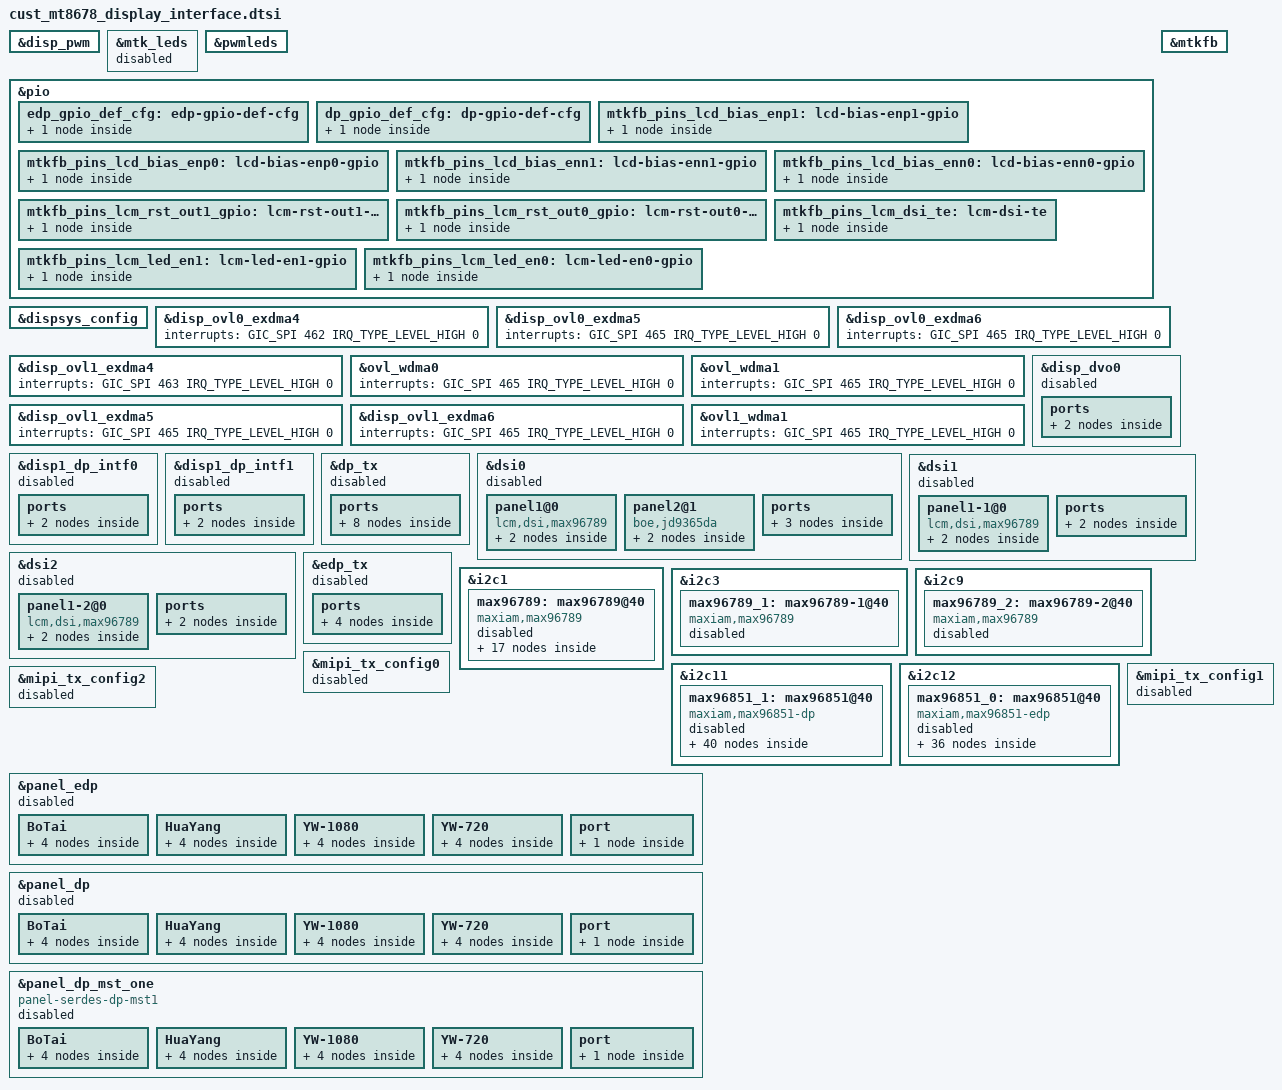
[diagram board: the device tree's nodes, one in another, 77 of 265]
// SPDX-License-Identifier: (GPL-2.0 OR MIT)
/*
 * Copyright (C) 2022 MediaTek Inc.
 */

&disp_pwm {
	status = "okay";
};
&mtk_leds {
	status = "disabled";
};
&pwmleds {
	status = "okay";
};

&pio {
	edp_gpio_def_cfg: edp-gpio-def-cfg{
		pins1 {
			pinmux = <PINMUX_GPIO8__FUNC_EDP_TX_HPD>;
		};
	};

	dp_gpio_def_cfg: dp-gpio-def-cfg {
		pins1 {
			pinmux = <PINMUX_GPIO118__FUNC_DP_TX_HPD>;
		};
	};

	mtkfb_pins_lcd_bias_enp1: lcd-bias-enp1-gpio {
		pins-cmd-dat {
			pinmux = <PINMUX_GPIO103__FUNC_GPIO103>;
			slew-rate = <1>;
			output-high;
		};
	};

	mtkfb_pins_lcd_bias_enp0: lcd-bias-enp0-gpio {
		pins-cmd-dat {
			pinmux = <PINMUX_GPIO103__FUNC_GPIO103>;
			slew-rate = <1>;
			output-low;
		};
	};

	mtkfb_pins_lcd_bias_enn1: lcd-bias-enn1-gpio {
		pins-cmd-dat {
			pinmux = <PINMUX_GPIO103__FUNC_GPIO103>;
			slew-rate = <1>;
			output-high;
		};
	};

	mtkfb_pins_lcd_bias_enn0: lcd-bias-enn0-gpio {
		pins-cmd-dat {
			pinmux = <PINMUX_GPIO103__FUNC_GPIO103>;
			slew-rate = <1>;
			output-low;
		};
	};

	mtkfb_pins_lcm_rst_out1_gpio: lcm-rst-out1-gpio {
		pins-cmd-dat {
			pinmux = <PINMUX_GPIO90__FUNC_GPIO90>;
			slew-rate = <1>;
			output-high;
		};
	};

	mtkfb_pins_lcm_rst_out0_gpio: lcm-rst-out0-gpio {
		pins-cmd-dat {
			pinmux = <PINMUX_GPIO90__FUNC_GPIO90>;
			slew-rate = <1>;
			output-low;
		};
	};
	mtkfb_pins_lcm_dsi_te: lcm-dsi-te {
		pins-cmd-dat {
			pinmux = <PINMUX_GPIO89__FUNC_DSI_TE>;
		};
	};

	mtkfb_pins_lcm_led_en1: lcm-led-en1-gpio {
		pins-cmd-dat {
			pinmux = <PINMUX_GPIO79__FUNC_GPIO79>;
			slew-rate = <1>;
			output-high;
		};
	};

	mtkfb_pins_lcm_led_en0: lcm-led-en0-gpio {
		pins-cmd-dat {
			pinmux = <PINMUX_GPIO79__FUNC_GPIO79>;
			slew-rate = <1>;
			output-low;
		};
	};
};

&mtkfb {
	pinctrl-names = "lcd_bias_enp1_gpio", "lcd_bias_enp0_gpio",
		"lcd_bias_enn1_gpio", "lcd_bias_enn0_gpio",
		"lcm_rst_out1_gpio", "lcm_rst_out0_gpio",
		"mode_te_te", "lcm_led_en1_gpio", "lcm_led_en0_gpio";
	pinctrl-0 = <&mtkfb_pins_lcd_bias_enp1>;
	pinctrl-1 = <&mtkfb_pins_lcd_bias_enp0>;
	pinctrl-2 = <&mtkfb_pins_lcd_bias_enn1>;
	pinctrl-3 = <&mtkfb_pins_lcd_bias_enn0>;
	pinctrl-4 = <&mtkfb_pins_lcm_rst_out1_gpio>;
	pinctrl-5 = <&mtkfb_pins_lcm_rst_out0_gpio>;
	pinctrl-6 = <&mtkfb_pins_lcm_dsi_te>;
	pinctrl-7 = <&mtkfb_pins_lcm_led_en1>;
	pinctrl-8 = <&mtkfb_pins_lcm_led_en0>;

	status = "okay";
};

&dispsys_config {
	pinctrl-names = "mode_te_te";
	pinctrl-0 = <&mtkfb_pins_lcm_dsi_te>;
	pd-others = <&disp1_mutex0>, <&disp_ovl0_exdma3>, <&disp_ovl1_exdma3>,
			<&disp_dpc>, <&mipi_tx_config0>, <&mipi_tx_config1>, <&mipi_tx_config2>;
	pd-names = "side_dispsys", "ovlsys", "side_ovlsys",
			"mminfra_in_dpc", "dsi_phy0", "dsi_phy1", "dsi_phy2";
	status = "okay";
};

&disp_ovl0_exdma4{
	interrupts = <GIC_SPI 462 IRQ_TYPE_LEVEL_HIGH 0>;
};

&disp_ovl0_exdma5 {
	interrupts = <GIC_SPI 465 IRQ_TYPE_LEVEL_HIGH 0>;
};

&disp_ovl0_exdma6 {
	interrupts = <GIC_SPI 465 IRQ_TYPE_LEVEL_HIGH 0>;
};

&disp_ovl1_exdma4{
	interrupts = <GIC_SPI 463 IRQ_TYPE_LEVEL_HIGH 0>;
};

&ovl_wdma0 {
	interrupts = <GIC_SPI 465 IRQ_TYPE_LEVEL_HIGH 0>;
};

&ovl_wdma1 {
	interrupts = <GIC_SPI 465 IRQ_TYPE_LEVEL_HIGH 0>;
};

&disp_ovl1_exdma5 {
	interrupts = <GIC_SPI 465 IRQ_TYPE_LEVEL_HIGH 0>;
};

&disp_ovl1_exdma6 {
	interrupts = <GIC_SPI 465 IRQ_TYPE_LEVEL_HIGH 0>;
};

&ovl1_wdma1 {
	interrupts = <GIC_SPI 465 IRQ_TYPE_LEVEL_HIGH 0>;
};

&disp_dvo0 {
	status = "disabled";
	ports {
		port {
			disp_dvo0_out: endpoint {
				remote-endpoint = <&edptx_in>;
			};
		};
	};
};

&disp1_dp_intf0 {
	status = "disabled";

	ports {
		port@0 {
			reg = <0>;
			disp1_dp_intf0_out: endpoint {
				remote-endpoint = <&dptx_in0>;
			};
		};
	};
};

&disp1_dp_intf1 {
	status = "disabled";

	ports {
		port@0 {
			reg = <0>;
			disp1_dp_intf1_out: endpoint {
				remote-endpoint = <&dptx_in1>;
			};
		};
	};
};

&dp_tx {
	pinctrl-names = "default";
	pinctrl-0 = <&dp_gpio_def_cfg>;
	status = "disabled";
	direct-dp;

	ports {
		port@0 {
			reg = <0>;
			dptx_in0: endpoint {
				remote-endpoint = <&disp1_dp_intf0_out>;
			};
		};

		port@1 {
			reg = <1>;
			dptx_in1: endpoint {
				remote-endpoint = <&disp1_dp_intf1_out>;
			};
		};

		port@2 {
			reg = <2>;
			dptx_out0: endpoint {
				remote-endpoint = <&serdes_dp_in0>;
			};
		};
		port@3 {
			reg = <3>;
			dptx_out1: endpoint {
				remote-endpoint = <&serdes_dp_mst_in1>;
			};
		};
	};
};

&dsi0 {
	status = "disabled";
	#address-cells = <1>;
	#size-cells = <0>;
	panel1@0 {
		compatible = "lcm,dsi,max96789";
		reg = <0>;

		ser = <&max96789>;
		port {
			panel_in1: endpoint {
				remote-endpoint = <&dsi_out>;
			};
		};
	};
	panel2@1 {
		compatible = "boe,jd9365da";
		reg = <1>;
		power-gpios = <&pio 79 0>;
		reset-gpios = <&pio 90 0>;
		pinctrl-names = "default";
		port {
			panel_in2: endpoint {
				remote-endpoint = <&dsi_out2>;
			};
		};
	};
	ports {
		port {
			dsi_out: endpoint@0 {
				remote-endpoint = <&panel_in1>;
			};

			dsi_out2: endpoint@1 {
				remote-endpoint = <&panel_in2>;
			};
		};
	};
};

&dsi1 {
	status = "disabled";
	#address-cells = <1>;
	#size-cells = <0>;
	panel1-1@0 {
		compatible = "lcm,dsi,max96789";
		reg = <0>;

		ser = <&max96789_1>;
		port {
			panel1_in: endpoint {
				remote-endpoint = <&dsi1_out>;
			};
		};
	};
	ports {
		port {
			dsi1_out: endpoint@0 {
				remote-endpoint = <&panel1_in>;
			};
		};
	};
};

&dsi2 {
	status = "disabled";
	#address-cells = <1>;
	#size-cells = <0>;
	panel1-2@0 {
		compatible = "lcm,dsi,max96789";
		reg = <0>;

		ser = <&max96789_2>;
		port {
			panel2_in: endpoint {
				remote-endpoint = <&dsi2_out>;
			};
		};
	};
	ports {
		port {
			dsi2_out: endpoint@0 {
				remote-endpoint = <&panel2_in>;
			};
		};
	};
};

&edp_tx {
	pinctrl-names = "default";
	pinctrl-0 = <&edp_gpio_def_cfg>;
	status = "disabled";
	max-lane-count = <4>;
	max-linkrate-mhz = <8100>;

	use-hpd = <1>;
	use-edid = <0>;
	external-monitor = <0>;

	ports {
		port@0 {
			reg = <0>;
			edptx_in: endpoint {
				remote-endpoint = <&disp_dvo0_out>;
			};
		};
		port@1 {
			reg = <1>;
			edptx_out: endpoint {
				remote-endpoint = <&serdes_edp_in>;
			};
		};
	};
};

&i2c1 {
	status = "okay";
	max96789: max96789@40 {
		compatible = "maxiam,max96789";
		status = "disabled";
		reg = <0x40>;
		reset-gpios = <&pio 37 0>;
		// only for test
		//interrupt-parent = <&pio>;
		//interrupts = <187 IRQ_TYPE_EDGE_RISING>;
		pinctrl-names = "default";
		setting = <&setting_compatible>;
		inited-in-lk = <1>;
	};
};

&i2c3 {
	status = "okay";
	max96789_1: max96789-1@40 {
		compatible = "maxiam,max96789";
		status = "disabled";
		reg = <0x40>;
		reset-gpios = <&pio 38 0>;
		pinctrl-names = "default";
		setting = <&setting_compatible>;
	};
};

&i2c9 {
	status = "okay";
	max96789_2: max96789-2@40 {
		compatible = "maxiam,max96789";
		status = "disabled";
		reg = <0x40>;
		reset-gpios = <&pio 24 0>;
		pinctrl-names = "default";
		setting = <&setting_compatible>;
	};
};

&i2c11 {
	status = "okay";
	max96851_1: max96851@40 {
		status = "disabled";
		compatible = "maxiam,max96851-dp";
		reg = <0x40>;
		pinctrl-names = "default";
		reset-gpios = <&pio 70 0>;

		panel-name = "HuaYang";
		use-for-dp = <1>;
		use-default-setting = <1>;
		ser-support-hotplug = <1>;
		ser-super-frame = <0>;
		ser-double-pixel = <0>;
		ser-dp-mst = <1>;
		support-touch = <1>;

		feature{
			feature-handle-num = <2>;
			feature-handle0{
				check-cmd = <0x01 0x01 0x1a 0xb 0x83 0x50 0x00 0x01 0x00 0x00 0x00 0x00 0x00 0x00 0xd4>;
				verify-cmd = <0x01 0x00 0x1a 0x02 0xf0 0x10>;
				feature-setting = "BoTai";
			};
			feature-handle1{
				check-cmd = <0x01 0x00 0x1a 0xb 0x83 0x50 0x00 0x01 0x00 0x00 0x00 0x00 0x00 0x00 0xd4>;
				verify-cmd = <0x01 0x00 0x1a 0x02 0xff 0xff>;
				feature-setting = "HuaYang";
			};
		};

		BoTai{
			serdes-dp-sst-settting{
				ser-init-cmd = <
					0 0x0100 0x61 0
					0 0x7000 0x00 0
					0 0x7019 0x00 0
					0 0x70a0 0x04 0
					0 0x7074 0x14 0
					0 0x7070 0x04 0
					0 0x7000 0x01 100
				>;
				des-i2c-addr = <0x4c>;
				des-init-cmd = <
					1 0x01ce 0x5e 2
					1 0x06ff 0x22 0
				>;
				touch-init-cmd =<
				>;
				bl-i2c-addr = <0x1a>;
				bl-on-cmd = <
					0x83 0x50 0x00 0x01 0x00 0x00 0x00 0x00 0x00 0x00 0xd4
				>;
				bl-off-cmd = <
					0x83 0x00 0x00 0x02 0x00 0x00 0x00 0x00 0x00 0x00 0x85
				>;
			};

			serdes-dp-superframe-setting{
				asymmetric-multi-view = <0>;
				symmetric-multi-view-setting{
					des-i2c-addr = <0x4c>;
					serdes-init-linka-cmd = <
						0 0x0028 0x88 0
						0 0x0032 0x08 100
						1 0x0000 0x94 0
					>;
					des-linka-i2c-addr = <0x4a>;
					des-linka-bl-i2c-addr = <0x1b>;
					des-linka-init-cmd = <
						2 0x01ce 0x5e 0
						2 0x01ea 0x05 0
						2 0x0042 0x36 0
						2 0x0043 0x34 0
						2 0x06ff 0x22 0
					>;
					des-linkb-i2c-addr = <0x48>;
					des-linkb-bl-i2c-addr = <0x1c>;
					serdes-init-linkb-cmd = <
						0 0x0028 0x08 0
						0 0x0032 0x88 100
						1 0x0000 0x90 0
					>;
					des-linkb-init-cmd = <
						3 0x01ce 0x5e 0
						3 0x01ea 0x05 0
						3 0x0050 0x01 0
						3 0x0042 0x38 0
						3 0x0043 0x34 0
						3 0x06ff 0x22 0
					>;
					ser-superframe-init-cmd = <
						0 0x0028 0x88 0
						0 0x0032 0x88 0
						0 0x0029 0x02 0
						0 0x0033 0x02 0
						0 0x05ce 0x37 0
						0 0x04d1 0xf8 0
						0 0x05d1 0xf8 0
						0 0x04cf 0xbf 0
						0 0x05cf 0xbf 0
						0 0x04d1 0xfc 0
						0 0x05d1 0xfc 0
						0 0x04ce 0x0f 0
						0 0x05ce 0x07 0
						0 0x0110 0x63 0
						0 0x04c0 0x80 0
						0 0x04c1 0x6b 0
						0 0x04c2 0x23 0
						0 0x04c3 0xc8 0
						0 0x04c4 0x08 0
						0 0x04c5 0x07 0
						0 0x04c6 0x00 0
						0 0x04c7 0x00 0
						0 0x04c8 0x80 0
						0 0x04c9 0x07 0
						0 0x04ca 0x38 0
						0 0x04cb 0x04 0
						0 0x05c0 0x80 0
						0 0x05c1 0x6b 0
						0 0x05c2 0x23 0
						0 0x05c3 0xc8 0
						0 0x05c4 0x08 0
						0 0x05c5 0x07 0
						0 0x05c6 0x80 0
						0 0x05c7 0x07 0
						0 0x05c8 0x00 0
						0 0x05c9 0x0f 0
						0 0x05ca 0x38 0
						0 0x05cb 0x04 0
						0 0x04d8 0x00 0
						0 0x04d9 0x0a 0
						0 0x04da 0x23 0
						0 0x04db 0x40 0
						0 0x04dc 0x10 0
						0 0x04dd 0x00 0
						0 0x04de 0x40 0
						0 0x04df 0x51 0
						0 0x04e0 0x00 0
						0 0x04e1 0x00 0
						0 0x04e2 0x00 0
						0 0x04e3 0x00 0
						0 0x04e4 0x28 0
						0 0x04e5 0x00 0
						0 0x04e6 0xf8 0
						0 0x04e7 0x07 0
						0 0x04e8 0x5c 0
						0 0x04e9 0x04 0
						0 0x04ea 0x00 0
						0 0x04eb 0x00 0
						0 0x04ec 0x00 0
						0 0x04ed 0x78 0
						0 0x04ee 0x00 0
						0 0x04ef 0x00 0
						0 0x04f0 0x80 0
						0 0x04f1 0x07 0
						0 0x04f2 0xa0 0
						0 0x04f3 0x00 0
						0 0x04f4 0x38 0
						0 0x04f5 0x04 0
						0 0x04f6 0x08 0
						0 0x04f7 0x24 0
						0 0x04f8 0x01 0
						0 0x05d8 0x00 0
						0 0x05d9 0x0a 0
						0 0x05da 0x23 0
						0 0x05db 0x40 0
						0 0x05dc 0x10 0
						0 0x05dd 0x00 0
						0 0x05de 0x40 0
						0 0x05df 0x51 0
						0 0x05e0 0x00 0
						0 0x05e1 0x00 0
						0 0x05e2 0x00 0
						0 0x05e3 0x00 0
						0 0x05e4 0x28 0
						0 0x05e5 0x00 0
						0 0x05e6 0xf8 0
						0 0x05e7 0x07 0
						0 0x05e8 0x5c 0
						0 0x05e9 0x04 0
						0 0x05ea 0x00 0
						0 0x05eb 0x00 0
						0 0x05ec 0x00 0
						0 0x05ed 0x78 0
						0 0x05ee 0x00 0
						0 0x05ef 0x00 0
						0 0x05f0 0x80 0
						0 0x05f1 0x07 0
						0 0x05f2 0xa0 0
						0 0x05f3 0x00 0
						0 0x05f4 0x38 0
						0 0x05f5 0x04 0
						0 0x05f6 0x08 0
						0 0x05f7 0x24 0
						0 0x05f8 0x01 0
						0 0x05cd 0x14 0
						0 0x6420 0x10 0
						0 0x7019 0x00 0
						0 0x7a14 0x00 0
						0 0x7000 0x00 0
						0 0x7054 0x01 100
						0 0x7074 0x14 0
						0 0x7070 0x04 0
						0 0x04d0 0x0a 0
						0 0x05d0 0x0a 0
						0 0x6064 0x0f 0
						0 0x6065 0x0f 0
						0 0x6164 0x0f 0
						0 0x6165 0x0f 0
						0 0x6264 0x0f 0
						0 0x6265 0x0f 0
						0 0x6364 0x0f 0
						0 0x6365 0x0f 0
						0 0x7000 0x01 100
						0 0x7a18 0x05 0
						0 0x7a28 0xff 0
						0 0x7a2a 0xff 0
						0 0x7a24 0xff 0
						0 0x7a27 0x0f 0
						0 0x7a14 0x01 0
						0 0x6421 0x01 0
						0 0x6420 0x11 100
						0 0x6420 0x10 100
						0 0x6420 0x11 0
					>;
					serdes-superframe-touch-init-cmd = <
					>;
					bl-i2c-addr = <0x1a>;
					bl-on-cmd = <
						0x83 0x50 0x00 0x01 0x00 0x00 0x00 0x00 0x00 0x00 0xd4
					>;
					bl-off-cmd = <
						0x83 0x00 0x00 0x02 0x00 0x00 0x00 0x00 0x00 0x00 0x85
					>;
				};
				asymmetric-multi-view-setting{
				};
			};

			serdes-dp-double-pixel-setting{
			};

			serdes-dp-mst-setting{
				des-i2c-addr = <0x4c>;
				serdes-init-linka-cmd = <
					0 0x0028 0x88 0
					0 0x0032 0x08 200
					1 0x0000 0x94 0
				>;
				des-linka-i2c-addr = <0x4a>;
				des-linka-bl-i2c-addr = <0x1b>;
				des-linka-init-cmd = <
					2 0x0050 0x00 0
					2 0x01ce 0x5e 0
					2 0x01ea 0x05 0
					2 0x0042 0x36 0
					2 0x0043 0x34 0
					2 0x06ff 0x22 0
				>;
				des-linkb-i2c-addr = <0x48>;
				des-linkb-bl-i2c-addr = <0x1c>;
				serdes-init-linkb-cmd = <
					0 0x0028 0x08 0
					0 0x0032 0x88 100
					1 0x0000 0x90 0
				>;
				des-linkb-init-cmd = <
					3 0x0050 0x01 0
					3 0x01ce 0x5e 0
					3 0x01ea 0x05 0
					3 0x0042 0x38 0
					3 0x0043 0x34 0
					3 0x06ff 0x22 0
				>;
				ser-mst-init-cmd = <
					0 0x0028 0x88 0
					0 0x0032 0x88 0
					0 0x6421 0x0f 0
					0 0x7f11 0x05 0
					0 0x7018 0x1e 0
					0 0x7904 0x01 0
					0 0x7908 0x02 0
					0 0x6420 0x10 0
					0 0x7a14 0x00 0
					0 0x7b14 0x00 0
					0 0x7000 0x00 0
					0 0x7054 0x01 100
					0 0x7074 0x14 0
					0 0x7070 0x04 100
					0 0x0100 0x61 0
					0 0x0110 0x63 0
					0 0x7000 0x01 100
					0 0x7a18 0x05 0
					0 0x7b18 0x05 0
					0 0x7c18 0x05 0
					0 0x7d18 0x05 0
					0 0x7a28 0xff 0
					0 0x7a2a 0xff 0
					0 0x7a24 0xff 0
					0 0x7a27 0x0f 0
					0 0x7b28 0xff 0
					0 0x7b2a 0xff 0
					0 0x7b24 0xff 0
					0 0x7b27 0x0f 0
					0 0x7a14 0x01 0
					0 0x7b14 0x01 0
					0 0x7b00 0x01 0
					0 0x6420 0x13 0
				>;
				dp-mst-touch-i2c-addr = <>;
				dp-mst-touch-init-cmd = <
				>;
				bl-i2c-addr = <0x1a>;
				bl-on-cmd = <
					0x83 0x50 0x00 0x01 0x00 0x00 0x00 0x00 0x00 0x00 0xd4
				>;
				bl-off-cmd = <
					0x83 0x00 0x00 0x02 0x00 0x00 0x00 0x00 0x00 0x00 0x85
				>;
			};
		};

		HuaYang{
			serdes-dp-sst-settting{
				ser-init-cmd = <
					0 0x0100 0x61 0
					0 0x7000 0x00 0
					0 0x7019 0x00 0
					0 0x70a0 0x04 0
					0 0x7074 0x14 0
					0 0x7070 0x04 0
					0 0x7000 0x01 100
				>;
				des-i2c-addr = <0x4c>;
				des-init-cmd = <
					1 0x01ce 0x4e 2
					1 0x06ff 0x22 0
				>;
				touch-init-cmd =<
				>;
				bl-i2c-addr = <0x1a>;
				bl-on-cmd = <
					0x83 0x50 0x00 0x01 0x00 0x00 0x00 0x00 0x00 0x00 0xd4
				>;
				bl-off-cmd = <
					0x83 0x00 0x00 0x02 0x00 0x00 0x00 0x00 0x00 0x00 0x85
				>;
			};

			serdes-dp-superframe-setting{
				asymmetric-multi-view = <0>;
				symmetric-multi-view-setting{
					des-i2c-addr = <0x4c>;
					serdes-init-linka-cmd = <
						0 0x0028 0x88 0
						0 0x0032 0x08 200
						1 0x0000 0x94 0
					>;
					des-linka-i2c-addr = <0x4a>;
					des-linka-bl-i2c-addr = <0x1b>;
					des-linka-init-cmd = <
						2 0x01ce 0x4e 0
						2 0x01ea 0x05 0
						2 0x0042 0x36 0
						2 0x0043 0x34 0
						2 0x06ff 0x22 0
					>;
					des-linkb-i2c-addr = <0x48>;
					des-linkb-bl-i2c-addr = <0x1c>;
					serdes-init-linkb-cmd = <
						0 0x0028 0x08 0
						0 0x0032 0x88 100
						1 0x0000 0x90 0
					>;
					des-linkb-init-cmd = <
						3 0x01ce 0x4e 0
						3 0x01ea 0x05 0
						3 0x0050 0x01 0
						3 0x0042 0x38 0
						3 0x0043 0x34 0
						3 0x06ff 0x22 0
					>;
					ser-superframe-init-cmd = <
						0 0x0028 0x88 0
						0 0x0032 0x88 0
						0 0x0029 0x02 0
						0 0x0033 0x02 0
						0 0x05ce 0x37 0
						0 0x04d1 0xf8 0
						0 0x05d1 0xf8 0
						0 0x04cf 0xbf 0
						0 0x05cf 0xbf 0
						0 0x04d1 0xfc 0
						0 0x05d1 0xfc 0
						0 0x04ce 0x0f 0
						0 0x05ce 0x07 0
						0 0x0110 0x63 0
						0 0x04c0 0x80 0
						0 0x04c1 0x6b 0
						0 0x04c2 0x23 0
						0 0x04c3 0xc8 0
						0 0x04c4 0x08 0
						0 0x04c5 0x07 0
						0 0x04c6 0x00 0
						0 0x04c7 0x00 0
						0 0x04c8 0x80 0
						0 0x04c9 0x07 0
						0 0x04ca 0x38 0
						0 0x04cb 0x04 0
						0 0x05c0 0x80 0
						0 0x05c1 0x6b 0
						0 0x05c2 0x23 0
						0 0x05c3 0xc8 0
						0 0x05c4 0x08 0
						0 0x05c5 0x07 0
						0 0x05c6 0x80 0
						0 0x05c7 0x07 0
						0 0x05c8 0x00 0
						0 0x05c9 0x0f 0
						0 0x05ca 0x38 0
						0 0x05cb 0x04 0
						0 0x04d8 0x00 0
						0 0x04d9 0x0a 0
						0 0x04da 0x23 0
						0 0x04db 0x40 0
						0 0x04dc 0x10 0
						0 0x04dd 0x00 0
						0 0x04de 0x40 0
						0 0x04df 0x51 0
						0 0x04e0 0x00 0
						0 0x04e1 0x00 0
						0 0x04e2 0x00 0
						0 0x04e3 0x00 0
						0 0x04e4 0x28 0
						0 0x04e5 0x00 0
						0 0x04e6 0xf8 0
						0 0x04e7 0x07 0
						0 0x04e8 0x5c 0
						0 0x04e9 0x04 0
						0 0x04ea 0x00 0
						0 0x04eb 0x00 0
						0 0x04ec 0x00 0
						0 0x04ed 0x78 0
						0 0x04ee 0x00 0
						0 0x04ef 0x00 0
						0 0x04f0 0x80 0
						0 0x04f1 0x07 0
						0 0x04f2 0xa0 0
						0 0x04f3 0x00 0
						0 0x04f4 0x38 0
						0 0x04f5 0x04 0
						0 0x04f6 0x08 0
						0 0x04f7 0x24 0
						0 0x04f8 0x01 0
						0 0x05d8 0x00 0
						0 0x05d9 0x0a 0
						0 0x05da 0x23 0
						0 0x05db 0x40 0
						0 0x05dc 0x10 0
						0 0x05dd 0x00 0
						0 0x05de 0x40 0
						0 0x05df 0x51 0
						0 0x05e0 0x00 0
						0 0x05e1 0x00 0
						0 0x05e2 0x00 0
						0 0x05e3 0x00 0
						0 0x05e4 0x28 0
						0 0x05e5 0x00 0
						0 0x05e6 0xf8 0
						0 0x05e7 0x07 0
						0 0x05e8 0x5c 0
						0 0x05e9 0x04 0
						0 0x05ea 0x00 0
						0 0x05eb 0x00 0
						0 0x05ec 0x00 0
						0 0x05ed 0x78 0
						0 0x05ee 0x00 0
						0 0x05ef 0x00 0
						0 0x05f0 0x80 0
						0 0x05f1 0x07 0
						0 0x05f2 0xa0 0
						0 0x05f3 0x00 0
						0 0x05f4 0x38 0
						0 0x05f5 0x04 0
						0 0x05f6 0x08 0
						0 0x05f7 0x24 0
						0 0x05f8 0x01 0
						0 0x05cd 0x14 0
						0 0x6420 0x10 0
						0 0x7019 0x00 0
						0 0x7a14 0x00 0
						0 0x7000 0x00 0
						0 0x7054 0x01 100
						0 0x7074 0x14 0
						0 0x7070 0x04 0
						0 0x04d0 0x0a 0
						0 0x05d0 0x0a 0
						0 0x6064 0x0f 0
						0 0x6065 0x0f 0
						0 0x6164 0x0f 0
						0 0x6165 0x0f 0
						0 0x6264 0x0f 0
						0 0x6265 0x0f 0
						0 0x6364 0x0f 0
						0 0x6365 0x0f 0
						0 0x7000 0x01 100
						0 0x7a18 0x05 0
						0 0x7a28 0xff 0
						0 0x7a2a 0xff 0
						0 0x7a24 0xff 0
						0 0x7a27 0x0f 0
						0 0x7a14 0x01 0
						0 0x6421 0x01 0
						0 0x6420 0x11 100
						0 0x6420 0x10 100
						0 0x6420 0x11 0
					>;
					serdes-superframe-touch-init-cmd = <
					>;
					bl-i2c-addr = <0x1a>;
					bl-on-cmd = <
						0x83 0x50 0x00 0x01 0x00 0x00 0x00 0x00 0x00 0x00 0xd4
					>;
					bl-off-cmd = <
						0x83 0x00 0x00 0x02 0x00 0x00 0x00 0x00 0x00 0x00 0x85
					>;
				};
				asymmetric-multi-view-setting{
				};
			};

			serdes-dp-double-pixel-setting{
			};

			serdes-dp-mst-setting{
				des-i2c-addr = <0x4c>;
				serdes-init-linka-cmd = <
					0 0x0028 0x88 0
					0 0x0032 0x08 100
					1 0x0000 0x94 0
				>;
				des-linka-i2c-addr = <0x4a>;
				des-linka-bl-i2c-addr = <0x1b>;
				des-linka-init-cmd = <
					2 0x0050 0x00 0
					2 0x01ce 0x4e 0
					2 0x01ea 0x05 0
					2 0x0042 0x36 0
					2 0x0043 0x34 0
					2 0x06ff 0x22 0
				>;
				des-linkb-i2c-addr = <0x48>;
				des-linkb-bl-i2c-addr = <0x1c>;
				serdes-init-linkb-cmd = <
					0 0x0028 0x08 0
					0 0x0032 0x88 200
					1 0x0000 0x90 0
				>;
				des-linkb-init-cmd = <
					3 0x0050 0x01 0
					3 0x01ce 0x4e 0
					3 0x01ea 0x05 0
					3 0x0042 0x38 0
					3 0x0043 0x34 0
					3 0x06ff 0x22 0
				>;
				ser-mst-init-cmd = <
					0 0x0028 0x88 0
					0 0x0032 0x88 0
					0 0x6421 0x0f 0
					0 0x7f11 0x05 0
					0 0x7018 0x1e 0
					0 0x7904 0x01 0
					0 0x7908 0x02 0
					0 0x6420 0x10 0
					0 0x7a14 0x00 0
					0 0x7b14 0x00 0
					0 0x7000 0x00 0
					0 0x7054 0x01 100
					0 0x7074 0x14 0
					0 0x7070 0x04 100
					0 0x0100 0x61 0
					0 0x0110 0x63 0
					0 0x7000 0x01 100
					0 0x7a18 0x05 0
					0 0x7b18 0x05 0
					0 0x7c18 0x05 0
					0 0x7d18 0x05 0
					0 0x7a28 0xff 0
					0 0x7a2a 0xff 0
					0 0x7a24 0xff 0
					0 0x7a27 0x0f 0
					0 0x7b28 0xff 0
					0 0x7b2a 0xff 0
					0 0x7b24 0xff 0
					0 0x7b27 0x0f 0
					0 0x7a14 0x01 0
					0 0x7b14 0x01 0
					0 0x7b00 0x01 0
					0 0x6420 0x13 0
				>;
				dp-mst-touch-i2c-addr = <>;
				dp-mst-touch-init-cmd = <
					2 0x0044 0x42 0	/* remap 0x14 to 0x21 */
					2 0x0045 0x28 0
					3 0x0044 0x44 0	/* remap 0x14 to 0x22 */
					3 0x0045 0x28 0
					0 0x0258 0x00 0	/*96851 INT linka  GPIO11 */
					0 0x0259 0xab 0
					0 0x025b 0x4b 0
					0 0x025b 0x22 0
					0 0x0260 0x00 0	/*96851 INT  linkb  GPIO12 */
					0 0x0261 0xac 0
					0 0x0262 0x4c 0
					0 0x0263 0x28 0
					2 0x020c 0x03 0	/* 96752 INT linka GPIO 4*/
					2 0x020d 0xab 0
					2 0x020e 0x4b 0
					3 0x020c 0x03 0	/* 96752 INT linkb GPIO 4*/
					3 0x020d 0xac 0
					3 0x020e 0x4c 0
				>;
				bl-i2c-addr = <0x1a>;
				bl-on-cmd = <
					0x83 0x50 0x00 0x01 0x00 0x00 0x00 0x00 0x00 0x00 0xd4
				>;
				bl-off-cmd = <
					0x83 0x00 0x00 0x02 0x00 0x00 0x00 0x00 0x00 0x00 0x85
				>;
			};
		};

		YW-1080{
			serdes-dp-sst-settting{
				ser-init-cmd = <
					0 0x0100 0x61 0
					0 0x7000 0x00 0
					0 0x7019 0x00 0
					0 0x70a0 0x04 0
					0 0x7074 0x14 0
					0 0x7070 0x04 0
					0 0x7000 0x01 100
				>;
				des-i2c-addr = <0x4a>;
				des-init-cmd = <
					1 0x0215 0x10 0
					1 0x0227 0x10 0
					1 0x020f 0x10 0
					1 0x021b 0x10 0
					1 0x020c 0x10 0
					1 0x0209 0x10 0
					1 0x0212 0x10 0
					1 0x005b 0x31 0
					1 0x0063 0x31 0
					1 0x006b 0x31 0
					1 0x0073 0x31 0
					1 0x007b 0x31 0
					1 0x008b 0x31 0
					1 0x00a3 0x31 0
					1 0x00ab 0x31 0
					1 0x0140 0x20 0
					1 0x0002 0x43 0
					1 0x01d2 0x22 0
					1 0x01d4 0x44 0
					1 0x0010 0x11 0
					1 0x01ce 0x5e 0
					1 0x01c8 0x38 0
					1 0x01c9 0x39 0
					1 0x01ca 0x3a 0
					1 0x0002 0x03 0
					1 0x0d00 0xf4 0
					1 0x0002 0x43 0
					1 0x0d00 0xf5 0
					1 0x01c8 0x18 0
					1 0x01c9 0x19 0
					1 0x01ca 0x1a 0
					1 0x06ff 0x22 0
				>;
				touch-init-cmd =<
					1 0x0206 0x03 0
					1 0x0207 0xab 0
					1 0x0208 0x4b 0
					0 0x0258 0x00 0
					0 0x0259 0xab 0
					0 0x025a 0x4b 0
					0 0x025b 0x22 0
				>;
				bl-i2c-addr = <0x1a>;
				bl-on-cmd = <
					0x83 0x50 0x00 0x01 0x00 0x00 0x00 0x00 0x00 0x00 0x00
				>;
				bl-off-cmd = <
					0x83 0x00 0x00 0x02 0x00 0x00 0x00 0x00 0x00 0x00 0x85
				>;
			};

			serdes-dp-superframe-setting{
				asymmetric-multi-view = <0>;
				symmetric-multi-view-setting{
					des-i2c-addr = <0x4a>;
					serdes-init-linka-cmd = <
					>;
					des-linka-i2c-addr = <0x4a>;
					des-linka-bl-i2c-addr = <0x1b>;
					des-linka-init-cmd = <
					>;
					des-linkb-i2c-addr = <0x48>;
					des-linkb-bl-i2c-addr = <0x1c>;
					serdes-init-linkb-cmd = <
					>;
					des-linkb-init-cmd = <
					>;
					ser-superframe-init-cmd = <
					>;
					serdes-superframe-touch-init-cmd = <
					>;
					bl-i2c-addr = <0x1a>;
					bl-on-cmd = <
						0x83 0x50 0x00 0x01 0x00 0x00 0x00 0x00 0x00 0x00 0x00
					>;
					bl-off-cmd = <
						0x83 0x00 0x00 0x02 0x00 0x00 0x00 0x00 0x00 0x00 0x85
					>;
				};
				asymmetric-multi-view-setting{
				};
			};

			serdes-dp-double-pixel-setting{
			};

			serdes-dp-mst-setting{
				des-i2c-addr = <0x4a>;
				serdes-init-linka-cmd = <
					0 0x0028 0x88 0
					0 0x0032 0x08 200
					1 0x0000 0x98 0
				>;
				des-linka-i2c-addr = <0x4c>;
				des-linka-bl-i2c-addr = <0x1b>;
				des-linka-init-cmd = <
					2 0x01ea 0x05 0
					2 0x0050 0x00 0
					2 0x0215 0x10 0
					2 0x0227 0x10 0
					2 0x020f 0x10 0
					2 0x021b 0x10 0
					2 0x020c 0x10 0
					2 0x0209 0x10 0
					2 0x0212 0x10 0
					2 0x005b 0x31 0
					2 0x0063 0x31 0
					2 0x006b 0x31 0
					2 0x0073 0x31 0
					2 0x007b 0x31 0
					2 0x008b 0x31 0
					2 0x00a3 0x31 0
					2 0x00ab 0x31 0
					2 0x0140 0x20 0
					2 0x0002 0x43 0
					2 0x01d2 0x22 0
					2 0x01d4 0x44 0
					2 0x0010 0x11 0
					2 0x01ce 0x5e 0
					2 0x01c8 0x38 0
					2 0x01c9 0x39 0
					2 0x01ca 0x3a 0
					2 0x0002 0x03 0
					2 0x0d00 0xf4 0
					2 0x0002 0x43 0
					2 0x0d00 0xf5 0
					2 0x01c8 0x18 0
					2 0x01c9 0x19 0
					2 0x01ca 0x1a 0
					2 0x06ff 0x22 0
				>;
				des-linkb-i2c-addr = <0x4d>;
				des-linkb-bl-i2c-addr = <0x1c>;
				serdes-init-linkb-cmd = <
					0 0x0028 0x08 0
					0 0x0032 0x88 200
					1 0x0000 0x9a 0
				>;
				des-linkb-init-cmd = <
					3 0x01ea 0x05 0
					3 0x0050 0x01 0
					3 0x0215 0x10 0
					3 0x0227 0x10 0
					3 0x020f 0x10 0
					3 0x021b 0x10 0
					3 0x020c 0x10 0
					3 0x0209 0x10 0
					3 0x0212 0x10 0
					3 0x005b 0x31 0
					3 0x0063 0x31 0
					3 0x006b 0x31 0
					3 0x0073 0x31 0
					3 0x007b 0x31 0
					3 0x008b 0x31 0
					3 0x00a3 0x31 0
					3 0x00ab 0x31 0
					3 0x0140 0x20 0
					3 0x0002 0x43 0
					3 0x01d2 0x22 0
					3 0x01d4 0x44 0
					3 0x0010 0x11 0
					3 0x01ce 0x5e 0
					3 0x01c8 0x38 0
					3 0x01c9 0x39 0
					3 0x01ca 0x3a 0
					3 0x0002 0x03 0
					3 0x0d00 0xf4 0
					3 0x0002 0x43 0
					3 0x0d00 0xf5 0
					3 0x01c8 0x18 0
					3 0x01c9 0x19 0
					3 0x01ca 0x1a 0
					3 0x06ff 0x22 0
				>;
				ser-mst-init-cmd = <
					0 0x0028 0x88 0
					0 0x0032 0x88 0
					0 0x6421 0x0f 0
					0 0x7f11 0x05 0
					0 0x7018 0x1e 0
					0 0x7904 0x01 0
					0 0x7908 0x02 0
					0 0x6420 0x10 0
					0 0x7a14 0x00 0
					0 0x7b14 0x00 0
					0 0x7000 0x00 0
					0 0x7054 0x01 100
					0 0x7074 0x14 0
					0 0x7070 0x04 100
					0 0x0100 0x61 0
					0 0x0110 0x63 0
					0 0x7000 0x01 100
					0 0x7a18 0x05 0
					0 0x7b18 0x05 0
					0 0x7c18 0x05 0
					0 0x7d18 0x05 0
					0 0x7a28 0xff 0
					0 0x7a2a 0xff 0
					0 0x7a24 0xff 0
					0 0x7a27 0x0f 0
					0 0x7b28 0xff 0
					0 0x7b2a 0xff 0
					0 0x7b24 0xff 0
					0 0x7b27 0x0f 0
					0 0x7a14 0x01 0
					0 0x7b14 0x01 0
					0 0x7b00 0x01 0
					0 0x6420 0x13 0
				>;
				dp-mst-touch-i2c-addr = <>;
				dp-mst-touch-init-cmd = <
				>;
				bl-i2c-addr = <0x1a>;
				bl-on-cmd = <
					0x83 0x50 0x00 0x01 0x00 0x00 0x00 0x00 0x00 0x00 0x00
				>;
				bl-off-cmd = <
					0x83 0x00 0x00 0x02 0x00 0x00 0x00 0x00 0x00 0x00 0x85
				>;
			};
		};

		YW-720{
			serdes-dp-sst-settting{
				ser-init-cmd = <
				>;
				des-i2c-addr = <0x4a>;
				des-init-cmd = <
				>;
				touch-init-cmd =<
				>;
				bl-i2c-addr = <0x1a>;
				bl-on-cmd = <
					0x83 0x50 0x00 0x01 0x00 0x00 0x00 0x00 0x00 0x00 0xd4
				>;
				bl-off-cmd = <
					0x83 0x00 0x00 0x02 0x00 0x00 0x00 0x00 0x00 0x00 0x85
				>;
			};

			serdes-dp-superframe-setting{
				asymmetric-multi-view = <0>;
				symmetric-multi-view-setting{
					des-i2c-addr = <0x4c>;
					serdes-init-linka-cmd = <
					>;
					des-linka-i2c-addr = <0x4a>;
					des-linka-bl-i2c-addr = <0x1b>;
					des-linka-init-cmd = <
					>;
					des-linkb-i2c-addr = <0x48>;
					des-linkb-bl-i2c-addr = <0x1c>;
					serdes-init-linkb-cmd = <
					>;
					des-linkb-init-cmd = <
					>;
					ser-superframe-init-cmd = <
					>;
					touch-init-cmd = <
					>;
					bl-i2c-addr = <0x1a>;
					bl-on-cmd = <
						0x83 0x50 0x00 0x01 0x00 0x00 0x00 0x00 0x00 0x00 0xd4
					>;
					bl-off-cmd = <
						0x83 0x00 0x00 0x02 0x00 0x00 0x00 0x00 0x00 0x00 0x85
					>;
				};
				asymmetric-multi-view-setting{
				};
			};

			serdes-dp-double-pixel-setting{
			};

			serdes-dp-mst-setting{
			};
		};

		ports {
			port@0 {
				reg = <0>;
				serdes_dp_in0: endpoint {
					remote-endpoint = <&dptx_out0>;
				};
			};

			port@1 {
				reg = <1>;
				serdes_dp_out: endpoint {
					remote-endpoint = <&panel_dp_in>;
				};
			};

			port@2 {
				reg = <2>;
				serdes_dp_mst_in1: endpoint {
					remote-endpoint = <&dptx_out1>;
				};
			};

			port@3 {
				reg = <3>;
				serdes_dp_mst_out1: endpoint {
					remote-endpoint = <&panel_dp_mst_in1>;
				};
			};
		};
	};
};

&i2c12 {
	status = "okay";
	max96851_0: max96851@40 {
		status = "disabled";
		compatible = "maxiam,max96851-edp";
		reg = <0x40>;
		pinctrl-names = "default";
		reset-gpios = <&pio 73 0>;

		panel-name = "HuaYang";
		use-for-dp = <0>;
		use-default-setting = <1>;
		ser-support-hotplug = <1>;
		ser-super-frame = <0>;
		ser-double-pixel = <0>;
		ser-dp-mst = <0>;
		support-touch = <1>;

		feature{
			feature-handle-num = <2>;
			feature-handle0{
				check-cmd = <0x01 0x01 0x1a 0xb 0x83 0x50 0x00 0x01 0x00 0x00 0x00 0x00 0x00 0x00 0xd4>;
				verify-cmd = <0x01 0x00 0x1a 0x02 0xf0 0x10>;
				feature-setting = "BoTai";
			};
			feature-handle1{
				check-cmd = <0x01 0x00 0x1a 0xb 0x83 0x50 0x00 0x01 0x00 0x00 0x00 0x00 0x00 0x00 0xd4>;
				verify-cmd = <0x01 0x00 0x1a 0x02 0xff 0xff>;
				feature-setting = "HuaYang";
			};
		};

		BoTai{
			serdes-dp-sst-settting{
				ser-init-cmd = <
					0 0x0100 0x61 0
					0 0x7000 0x00 0
					0 0x7019 0x00 0
					0 0x70a0 0x04 0
					0 0x7074 0x14 0
					0 0x7070 0x04 0
					0 0x7000 0x01 100
				>;
				des-i2c-addr = <0x4c>;
				des-init-cmd = <
					1 0x01ce 0x5e 2
					1 0x06ff 0x22 0
				>;
				touch-init-cmd =<
				>;
				bl-i2c-addr = <0x1a>;
				bl-on-cmd = <
					0x83 0x50 0x00 0x01 0x00 0x00 0x00 0x00 0x00 0x00 0xd4
				>;
				bl-off-cmd = <
					0x83 0x00 0x00 0x02 0x00 0x00 0x00 0x00 0x00 0x00 0x85
				>;
			};

			serdes-dp-superframe-setting{
				asymmetric-multi-view = <0>;
				symmetric-multi-view-setting{
					des-i2c-addr = <0x4c>;
					serdes-init-linka-cmd = <
						0 0x0028 0x88 0
						0 0x0032 0x08 100
						1 0x0000 0x94 0
					>;
					des-linka-i2c-addr = <0x4a>;
					des-linka-bl-i2c-addr = <0x1b>;
					des-linka-init-cmd = <
						2 0x01ce 0x5e 0
						2 0x01ea 0x05 0
						2 0x0042 0x36 0
						2 0x0043 0x34 0
						2 0x06ff 0x22 0
					>;
					des-linkb-i2c-addr = <0x48>;
					des-linkb-bl-i2c-addr = <0x1c>;
					serdes-init-linkb-cmd = <
						0 0x0028 0x08 0
						0 0x0032 0x88 100
						1 0x0000 0x90 0
					>;
					des-linkb-init-cmd = <
						3 0x01ce 0x5e 0
						3 0x01ea 0x05 0
						3 0x0050 0x01 0
						3 0x0042 0x38 0
						3 0x0043 0x34 0
						3 0x06ff 0x22 0
					>;
					ser-superframe-init-cmd = <
						0 0x0028 0x88 0
						0 0x0032 0x88 0
						0 0x0029 0x02 0
						0 0x0033 0x02 0
						0 0x05ce 0x37 0
						0 0x04d1 0xf8 0
						0 0x05d1 0xf8 0
						0 0x04cf 0xbf 0
						0 0x05cf 0xbf 0
						0 0x04d1 0xfc 0
						0 0x05d1 0xfc 0
						0 0x04ce 0x0f 0
						0 0x05ce 0x07 0
						0 0x0110 0x63 0
						0 0x04c0 0x80 0
						0 0x04c1 0x6b 0
						0 0x04c2 0x23 0
						0 0x04c3 0xc8 0
						0 0x04c4 0x08 0
						0 0x04c5 0x07 0
						0 0x04c6 0x00 0
						0 0x04c7 0x00 0
						0 0x04c8 0x80 0
						0 0x04c9 0x07 0
						0 0x04ca 0x38 0
						0 0x04cb 0x04 0
						0 0x05c0 0x80 0
						0 0x05c1 0x6b 0
						0 0x05c2 0x23 0
						0 0x05c3 0xc8 0
						0 0x05c4 0x08 0
						0 0x05c5 0x07 0
						0 0x05c6 0x80 0
						0 0x05c7 0x07 0
						0 0x05c8 0x00 0
						0 0x05c9 0x0f 0
						0 0x05ca 0x38 0
						0 0x05cb 0x04 0
						0 0x04d8 0x00 0
						0 0x04d9 0x0a 0
						0 0x04da 0x23 0
						0 0x04db 0x40 0
						0 0x04dc 0x10 0
						0 0x04dd 0x00 0
						0 0x04de 0x40 0
						0 0x04df 0x51 0
						0 0x04e0 0x00 0
						0 0x04e1 0x00 0
						0 0x04e2 0x00 0
						0 0x04e3 0x00 0
						0 0x04e4 0x28 0
						0 0x04e5 0x00 0
						0 0x04e6 0xf8 0
						0 0x04e7 0x07 0
						0 0x04e8 0x5c 0
						0 0x04e9 0x04 0
						0 0x04ea 0x00 0
						0 0x04eb 0x00 0
						0 0x04ec 0x00 0
						0 0x04ed 0x78 0
						0 0x04ee 0x00 0
						0 0x04ef 0x00 0
						0 0x04f0 0x80 0
						0 0x04f1 0x07 0
						0 0x04f2 0xa0 0
						0 0x04f3 0x00 0
						0 0x04f4 0x38 0
						0 0x04f5 0x04 0
						0 0x04f6 0x08 0
						0 0x04f7 0x24 0
						0 0x04f8 0x01 0
						0 0x05d8 0x00 0
						0 0x05d9 0x0a 0
						0 0x05da 0x23 0
						0 0x05db 0x40 0
						0 0x05dc 0x10 0
						0 0x05dd 0x00 0
						0 0x05de 0x40 0
						0 0x05df 0x51 0
						0 0x05e0 0x00 0
						0 0x05e1 0x00 0
						0 0x05e2 0x00 0
						0 0x05e3 0x00 0
						0 0x05e4 0x28 0
						0 0x05e5 0x00 0
						0 0x05e6 0xf8 0
						0 0x05e7 0x07 0
						0 0x05e8 0x5c 0
						0 0x05e9 0x04 0
						0 0x05ea 0x00 0
						0 0x05eb 0x00 0
						0 0x05ec 0x00 0
						0 0x05ed 0x78 0
						0 0x05ee 0x00 0
						0 0x05ef 0x00 0
						0 0x05f0 0x80 0
						0 0x05f1 0x07 0
						0 0x05f2 0xa0 0
						0 0x05f3 0x00 0
						0 0x05f4 0x38 0
						0 0x05f5 0x04 0
						0 0x05f6 0x08 0
						0 0x05f7 0x24 0
						0 0x05f8 0x01 0
						0 0x05cd 0x14 0
						0 0x6420 0x10 0
						0 0x7019 0x00 0
						0 0x7a14 0x00 0
						0 0x7000 0x00 0
						0 0x7054 0x01 100
						0 0x7074 0x14 0
						0 0x7070 0x04 0
						0 0x04d0 0x0a 0
						0 0x05d0 0x0a 0
						0 0x6064 0x0f 0
						0 0x6065 0x0f 0
						0 0x6164 0x0f 0
						0 0x6165 0x0f 0
						0 0x6264 0x0f 0
						0 0x6265 0x0f 0
						0 0x6364 0x0f 0
						0 0x6365 0x0f 0
						0 0x7000 0x01 100
						0 0x7a18 0x05 0
						0 0x7a28 0xff 0
						0 0x7a2a 0xff 0
						0 0x7a24 0xff 0
						0 0x7a27 0x0f 0
						0 0x7a14 0x01 0
						0 0x6421 0x01 0
						0 0x6420 0x11 100
						0 0x6420 0x10 100
						0 0x6420 0x11 0
					>;
					serdes-superframe-touch-init-cmd = <
					>;
					bl-i2c-addr = <0x1a>;
					bl-on-cmd = <
						0x83 0x50 0x00 0x01 0x00 0x00 0x00 0x00 0x00 0x00 0xd4
					>;
					bl-off-cmd = <
						0x83 0x00 0x00 0x02 0x00 0x00 0x00 0x00 0x00 0x00 0x85
					>;
				};
				asymmetric-multi-view-setting{
				};
			};

			serdes-dp-double-pixel-setting{
			};

			serdes-dp-mst-setting{
			};
		};

		HuaYang{
			serdes-dp-sst-settting{
				ser-init-cmd = <
					0 0x0100 0x61 0
					0 0x7000 0x00 0
					0 0x7019 0x00 0
					0 0x70a0 0x04 0
					0 0x7074 0x14 0
					0 0x7070 0x04 0
					0 0x7000 0x01 100
				>;
				des-i2c-addr = <0x4c>;
				des-init-cmd = <
					1 0x01ce 0x4e 2
					1 0x06ff 0x22 0
				>;
				touch-init-cmd =<
					0 0x0258 0x00 0   /*96851 INT linka  GPIO11 */
					0 0x0259 0xab 0
					0 0x025b 0x4b 0
					0 0x025b 0x22 0
					0 0x0260 0x00 0	  /*96851 INT  linkb  GPIO12 */
					0 0x0261 0xac 0
					0 0x0262 0x4c 0
					0 0x0263 0x28 0
					1 0x020c 0x03 0   /* 96752 INT linka GPIO 4*/
					1 0x020d 0xab 0
					1 0x020e 0x4b 0
				>;
				bl-i2c-addr = <0x1a>;
				bl-on-cmd = <
					0x83 0x50 0x00 0x01 0x00 0x00 0x00 0x00 0x00 0x00 0xd4
				>;
				bl-off-cmd = <
					0x83 0x00 0x00 0x02 0x00 0x00 0x00 0x00 0x00 0x00 0x85
				>;
			};

			serdes-dp-superframe-setting{
				asymmetric-multi-view = <0>;
				symmetric-multi-view-setting{
					des-i2c-addr = <0x4c>;
					serdes-init-linka-cmd = <
						0 0x0028 0x88 0
						0 0x0032 0x08 100
						1 0x0000 0x94 0
					>;
					des-linka-i2c-addr = <0x4a>;
					des-linka-bl-i2c-addr = <0x1b>;
					des-linka-init-cmd = <
						2 0x01ce 0x4e 0
						2 0x01ea 0x05 0
						2 0x0042 0x36 0
						2 0x0043 0x34 0
					>;
					des-linkb-i2c-addr = <0x48>;
					des-linkb-bl-i2c-addr = <0x1c>;
					serdes-init-linkb-cmd = <
						0 0x0028 0x08 0
						0 0x0032 0x88 100
						1 0x0000 0x90 0
					>;
					des-linkb-init-cmd = <
						3 0x01ce 0x4e 0
						3 0x01ea 0x05 0
						3 0x0050 0x01 0
						3 0x0042 0x38 0
						3 0x0043 0x34 0
					>;
					ser-superframe-init-cmd = <
						0 0x0028 0x88 0
						0 0x0032 0x88 0
						0 0x0029 0x02 0
						0 0x0033 0x02 0
						0 0x05ce 0x37 0
						0 0x04d1 0xf8 0
						0 0x05d1 0xf8 0
						0 0x04cf 0xbf 0
						0 0x05cf 0xbf 0
						0 0x04d1 0xfc 0
						0 0x05d1 0xfc 0
						0 0x04ce 0x0f 0
						0 0x05ce 0x07 0
						0 0x0110 0x63 0
						0 0x04c0 0x80 0
						0 0x04c1 0x6b 0
						0 0x04c2 0x23 0
						0 0x04c3 0xc8 0
						0 0x04c4 0x08 0
						0 0x04c5 0x07 0
						0 0x04c6 0x00 0
						0 0x04c7 0x00 0
						0 0x04c8 0x80 0
						0 0x04c9 0x07 0
						0 0x04ca 0x38 0
						0 0x04cb 0x04 0
						0 0x05c0 0x80 0
						0 0x05c1 0x6b 0
						0 0x05c2 0x23 0
						0 0x05c3 0xc8 0
						0 0x05c4 0x08 0
						0 0x05c5 0x07 0
						0 0x05c6 0x80 0
						0 0x05c7 0x07 0
						0 0x05c8 0x00 0
						0 0x05c9 0x0f 0
						0 0x05ca 0x38 0
						0 0x05cb 0x04 0
						0 0x04d8 0x00 0
						0 0x04d9 0x0a 0
						0 0x04da 0x23 0
						0 0x04db 0x40 0
						0 0x04dc 0x10 0
						0 0x04dd 0x00 0
						0 0x04de 0x40 0
						0 0x04df 0x51 0
						0 0x04e0 0x00 0
						0 0x04e1 0x00 0
						0 0x04e2 0x00 0
						0 0x04e3 0x00 0
						0 0x04e4 0x28 0
						0 0x04e5 0x00 0
						0 0x04e6 0xf8 0
						0 0x04e7 0x07 0
						0 0x04e8 0x5c 0
						0 0x04e9 0x04 0
						0 0x04ea 0x00 0
						0 0x04eb 0x00 0
						0 0x04ec 0x00 0
						0 0x04ed 0x78 0
						0 0x04ee 0x00 0
						0 0x04ef 0x00 0
						0 0x04f0 0x80 0
						0 0x04f1 0x07 0
						0 0x04f2 0xa0 0
						0 0x04f3 0x00 0
						0 0x04f4 0x38 0
						0 0x04f5 0x04 0
						0 0x04f6 0x08 0
						0 0x04f7 0x24 0
						0 0x04f8 0x01 0
						0 0x05d8 0x00 0
						0 0x05d9 0x0a 0
						0 0x05da 0x23 0
						0 0x05db 0x40 0
						0 0x05dc 0x10 0
						0 0x05dd 0x00 0
						0 0x05de 0x40 0
						0 0x05df 0x51 0
						0 0x05e0 0x00 0
						0 0x05e1 0x00 0
						0 0x05e2 0x00 0
						0 0x05e3 0x00 0
						0 0x05e4 0x28 0
						0 0x05e5 0x00 0
						0 0x05e6 0xf8 0
						0 0x05e7 0x07 0
						0 0x05e8 0x5c 0
						0 0x05e9 0x04 0
						0 0x05ea 0x00 0
						0 0x05eb 0x00 0
						0 0x05ec 0x00 0
						0 0x05ed 0x78 0
						0 0x05ee 0x00 0
						0 0x05ef 0x00 0
						0 0x05f0 0x80 0
						0 0x05f1 0x07 0
						0 0x05f2 0xa0 0
						0 0x05f3 0x00 0
						0 0x05f4 0x38 0
						0 0x05f5 0x04 0
						0 0x05f6 0x08 0
						0 0x05f7 0x24 0
						0 0x05f8 0x01 0
						0 0x05cd 0x14 0
						0 0x6420 0x10 0
						0 0x7019 0x00 0
						0 0x7a14 0x00 0
						0 0x7000 0x00 0
						0 0x7054 0x01 100
						0 0x7074 0x14 0
						0 0x7070 0x04 0
						0 0x04d0 0x0a 0
						0 0x05d0 0x0a 0
						0 0x6064 0x0f 0
						0 0x6065 0x0f 0
						0 0x6164 0x0f 0
						0 0x6165 0x0f 0
						0 0x6264 0x0f 0
						0 0x6265 0x0f 0
						0 0x6364 0x0f 0
						0 0x6365 0x0f 0
						0 0x7000 0x01 100
						0 0x7a18 0x05 0
						0 0x7a28 0xff 0
						0 0x7a2a 0xff 0
						0 0x7a24 0xff 0
						0 0x7a27 0x0f 0
						0 0x7a14 0x01 0
						0 0x6421 0x01 0
						0 0x6420 0x11 100
						0 0x6420 0x10 100
						0 0x6420 0x11 0
					>;
					serdes-superframe-touch-init-cmd = <
					>;
					bl-i2c-addr = <0x1a>;
					bl-on-cmd = <
						0x83 0x50 0x00 0x01 0x00 0x00 0x00 0x00 0x00 0x00 0xd4
					>;
					bl-off-cmd = <
						0x83 0x00 0x00 0x02 0x00 0x00 0x00 0x00 0x00 0x00 0x85
					>;
				};
				asymmetric-multi-view-setting{
				};
			};

			serdes-dp-double-pixel-setting{
			};

			serdes-dp-mst-setting{
			};
		};

		YW-1080{
			serdes-dp-sst-settting{
				ser-init-cmd = <
					0 0x0100 0x61 0
					0 0x7000 0x00 0
					0 0x7019 0x00 0
					0 0x70a0 0x04 0
					0 0x7074 0x14 0
					0 0x7070 0x04 0
					0 0x7000 0x01 100
				>;
				des-i2c-addr = <0x4a>;
				des-init-cmd = <
					1 0x0215 0x10 0
					1 0x0227 0x10 0
					1 0x020f 0x10 0
					1 0x021b 0x10 0
					1 0x020c 0x10 0
					1 0x0209 0x10 0
					1 0x0212 0x10 0
					1 0x005b 0x31 0
					1 0x0063 0x31 0
					1 0x006b 0x31 0
					1 0x0073 0x31 0
					1 0x007b 0x31 0
					1 0x008b 0x31 0
					1 0x00a3 0x31 0
					1 0x00ab 0x31 0
					1 0x0140 0x20 0
					1 0x0002 0x43 0
					1 0x01d2 0x22 0
					1 0x01d4 0x44 0
					1 0x0010 0x11 0
					1 0x01ce 0x5e 0
					1 0x01c8 0x38 0
					1 0x01c9 0x39 0
					1 0x01ca 0x3a 0
					1 0x0002 0x03 0
					1 0x0d00 0xf4 0
					1 0x0002 0x43 0
					1 0x0d00 0xf5 0
					1 0x01c8 0x18 0
					1 0x01c9 0x19 0
					1 0x01ca 0x1a 0
				>;
				touch-init-cmd =<
					1 0x0206 0x03 0
					1 0x0207 0xab 0
					1 0x0208 0x4b 0
					0 0x0258 0x00 0
					0 0x0259 0xab 0
					0 0x025a 0x4b 0
					0 0x025b 0x22 0
				>;
				bl-i2c-addr = <0x1a>;
				bl-on-cmd = <
					0x83 0x50 0x00 0x01 0x00 0x00 0x00 0x00 0x00 0x00 0x00
				>;
				bl-off-cmd = <
					0x83 0x00 0x00 0x02 0x00 0x00 0x00 0x00 0x00 0x00 0x85
				>;
			};

			serdes-dp-superframe-setting{
				asymmetric-multi-view = <0>;
				symmetric-multi-view-setting{
					des-i2c-addr = <0x4a>;
					serdes-init-linka-cmd = <
					>;
					des-linka-i2c-addr = <0x4a>;
					des-linka-bl-i2c-addr = <0x1b>;
					des-linka-init-cmd = <
					>;
					des-linkb-i2c-addr = <0x48>;
					des-linkb-bl-i2c-addr = <0x1c>;
					serdes-init-linkb-cmd = <
					>;
					des-linkb-init-cmd = <
					>;
					ser-superframe-init-cmd = <
					>;
					serdes-superframe-touch-init-cmd = <
					>;
					bl-i2c-addr = <0x1a>;
					bl-on-cmd = <
						0x83 0x50 0x00 0x01 0x00 0x00 0x00 0x00 0x00 0x00 0x00
					>;
					bl-off-cmd = <
						0x83 0x00 0x00 0x02 0x00 0x00 0x00 0x00 0x00 0x00 0x85
					>;
				};
				asymmetric-multi-view-setting{
				};
			};

			serdes-dp-double-pixel-setting{
			};

			serdes-dp-mst-setting{
			};
		};

		YW-720{
			serdes-dp-sst-settting{
				ser-init-cmd = <
				>;
				des-i2c-addr = <0x4a>;
				des-init-cmd = <
				>;
				touch-init-cmd =<
				>;
				bl-i2c-addr = <0x1a>;
				bl-on-cmd = <
					0x83 0x50 0x00 0x01 0x00 0x00 0x00 0x00 0x00 0x00 0xd4
				>;
				bl-off-cmd = <
					0x83 0x00 0x00 0x02 0x00 0x00 0x00 0x00 0x00 0x00 0x85
				>;
			};

			serdes-dp-superframe-setting{
				asymmetric-multi-view = <0>;
				symmetric-multi-view-setting{
					des-i2c-addr = <0x4c>;
					serdes-init-linka-cmd = <
					>;
					des-linka-i2c-addr = <0x4a>;
					des-linka-bl-i2c-addr = <0x1b>;
					des-linka-init-cmd = <
					>;
					des-linkb-i2c-addr = <0x48>;
					des-linkb-bl-i2c-addr = <0x1c>;
					serdes-init-linkb-cmd = <
					>;
					des-linkb-init-cmd = <
					>;
					ser-superframe-init-cmd = <
					>;
					serdes-superframe-touch-init-cmd = <
					>;
					bl-i2c-addr = <0x1a>;
					bl-on-cmd = <
						0x83 0x50 0x00 0x01 0x00 0x00 0x00 0x00 0x00 0x00 0xd4
					>;
					bl-off-cmd = <
						0x83 0x00 0x00 0x02 0x00 0x00 0x00 0x00 0x00 0x00 0x85
					>;
				};
				asymmetric-multi-view-setting{
				};
			};

			serdes-dp-double-pixel-setting{
			};

			serdes-dp-mst-setting{
			};
		};

		ports {
			port@0 {
				reg = <0>;
				serdes_edp_in: endpoint {
					remote-endpoint = <&edptx_out>;
				};
			};

			port@1 {
				reg = <1>;
				serdes_edp_out: endpoint {
					remote-endpoint = <&panel_edp_in>;
				};
			};
		};
	};
};

&max96789 {
	setting_compatible: compatible-node {
		comp-cmd = <
			0x01 0x1a 0x0b 0x83 0x50 0x00 0x01 0x00 0x00 0x00 0x00 0x00 0x00 0xd4
			0x00 0x1a 0x0b
		>;
		comp-exp {
			comp-setting =  <0xf0 0x10 &setting_bt>,
							<0xff 0xff &setting_hy>,
							<0xff 0x00 &setting_yw_1080p>;
		};
	};

	setting_yw_1080p: setting@0 {
		ser-dual-link = <0>;

		ser-init-cmd = <
			0x0002 0x03 0x0
			0x1404 0x29 0x0
			0x1504 0x29 0x0
			0x14a4 0xc8 0x0
			0x15a4 0xc8 0x0
			0x140a 0x00 0x0
			0x150a 0x00 0x0
			0x140b 0x00 0x0
			0x150b 0x00 0x0
			0x0330 0x04 0x0
			0x0331 0x33 0x0
			0x0333 0xe4 0x0
			0x0308 0x7c 0x0
			0x0053 0x10 0x0
			0x005b 0x12 0x0
			0x0140 0x20 0x0
			0x0002 0x53 0x0
			0x0010 0x11 0x64
			0x02dc 0x04 0x0
			0x02dd 0x1e 0x0
			0x02de 0x5e 0x0
		>;
		des-link-status-cmd = <
			0x001f 0x18 0x0
		>;
		desdef {
			des-i2c-addr = <0x4a>;
			des-init-cmd = <
				0x0215 0x10 0x0
				0x0227 0x10 0x0
				0x020f 0x10 0x0
				0x021b 0x10 0x0
				0x020c 0x10 0x0
				0x0209 0x10 0x0
				0x0212 0x10 0x0
				0x005b 0x31 0x0
				0x0063 0x31 0x0
				0x006b 0x31 0x0
				0x0073 0x31 0x0
				0x007b 0x31 0x0
				0x008b 0x31 0x0
				0x00a3 0x31 0x0
				0x00ab 0x31 0x0
				0x0140 0x20 0x0
				0x0002 0x43 0x0
				0x01d2 0x22 0x0
				0x01d4 0x44 0x0
				0x0010 0x11 0x0
				0x01ce 0x5e 0x0
				0x01c8 0x38 0x0
				0x01c9 0x39 0x0
				0x01ca 0x3a 0x0
				0x0002 0x03 0x0
				0x0d00 0xf4 0x0
				0x0002 0x43 0x0
				0x0d00 0xf5 0x0
				0x01c8 0x18 0x0
				0x01c9 0x19 0x0
				0x01ca 0x1a 0x0
				0x0206 0x0b 0x0
				0x0207 0x7e 0x0
				0x0208 0x5e 0x0
			>;
			panel-mode-setting {
				panel-mode-width = <1920>;
				panel-mode-height = <1080>;
				panel-mode-hfp = <112>;
				panel-mode-hsa = <24>;
				panel-mode-hbp = <32>;
				panel-mode-vfp = <16>;
				panel-mode-vsa = <3>;
				panel-mode-vbp = <24>;
				panel-mode-vrefresh = <60>;
				panel-mode-pll = <478>;
				panel-mode-lppf = <1>;
				panel-mode-width-mm = <129>;
				panel-mode-height-mm = <64>;
			};
		};
	};
	setting_bt: setting1 {
		ser-super-frame = <0>;

		ser-init-cmd = <
			0x0001 0x08 0x00
			0x0203 0x00 0x00
			0x1404 0x29 0x00
			0x1504 0x29 0x00
			0x14a4 0xc8 0x00
			0x15a4 0xc8 0x00
			0x140a 0x00 0x00
			0x150a 0x00 0x00
			0x140b 0x00 0x00
			0x150b 0x00 0x00
			0x0330 0x04 0x00
			0x0331 0x33 0x00
			0x0333 0xe4 0x00
			0x0308 0x7c 0x00
			0x0053 0x10 0x00
			0x005b 0x12 0x0a
			0x0140 0x20 0x00
			0x0002 0x53 0x00
			0x0010 0x31 0x40
		>;
		ser-deinit-cmd = <
			0x0010 0x80 0x20
		>;
		des-link-status-cmd = <
			0x001f 0x18 0x0
		>;
		desdef {
			des-i2c-addr = <0x4c>;
			bl-i2c-addr = <0x1a>;
			bl-dummy-i2c-addr = <0x1f>;
			des-init-cmd = <
				0x06ff 0x11 0x0
				0x01ce 0x5e 0x0
			>;
			link-indicate-cmd = <
				0x06ff 0x11 0x0
			>;
			bl-on-cmd = <
				0x83 0x50 0x00 0x01 0x00 0x00 0x00 0x00 0x00 0x00 0xd4
			>;
			bl-off-cmd = <
				0x83 0x00 0x00 0x02 0x00 0x00 0x00 0x00 0x00 0x00 0x85
			>;
			panel-mode-setting {
				panel-mode-width = <1920>;
				panel-mode-height = <1080>;
				panel-mode-hfp = <40>;
				panel-mode-hsa = <42>;
				panel-mode-hbp = <78>;
				panel-mode-vfp = <24>;
				panel-mode-vsa = <3>;
				panel-mode-vbp = <9>;
				panel-mode-vrefresh = <60>;
				panel-mode-lppf = <1>;
				panel-mode-width-mm = <129>;
				panel-mode-height-mm = <64>;
			};
		};
	};
	setting_hy: setting2 {
		ser-super-frame = <0>;

		ser-init-cmd = <
			0x0001 0x08 0x00
			0x0203 0x00 0x00
			0x1404 0x29 0x00
			0x1504 0x29 0x00
			0x14a4 0xc8 0x00
			0x15a4 0xc8 0x00
			0x140a 0x00 0x00
			0x150a 0x00 0x00
			0x140b 0x00 0x00
			0x150b 0x00 0x00
			0x0330 0x04 0x00
			0x0331 0x33 0x00
			0x0333 0xe4 0x00
			0x0308 0x7c 0x00
			0x0053 0x10 0x00
			0x005b 0x12 0x0a
			0x0140 0x20 0x00
			0x0002 0x53 0x00
			0x0010 0x31 0x40
			0x02dc 0x04 0x00    /* 96789 huayang tp ser int GPIO10 */
			0x02dd 0xaa 0x00    /* 96789 huayang tp ser int GPIO10 */
			0x02de 0x6a 0x00    /* 96789 huayang tp ser int GPIO10 */
		>;
		ser-deinit-cmd = <
			0x0010 0x80 0x20
		>;
		des-link-status-cmd = <
			0x001f 0x18 0x0
		>;
		desdef {
			des-i2c-addr = <0x4c>;
			bl-i2c-addr = <0x1a>;
			bl-dummy-i2c-addr = <0x1f>;
			des-init-cmd = <
				0x06ff 0x11 0x0
				0x01ce 0x4e 0x0
				0x020c 0x03 0  /* 96752 huayang tp des int GPIO4 */
				0x020d 0xaa 0  /* 96752 huayang tp des int GPIO4 */
				0x020e 0x4a 0  /* 96752 huayang tp des int GPIO4 */
			>;
			link-indicate-cmd = <
				0x06ff 0x11 0x0
			>;
			bl-on-cmd = <
				0x83 0x50 0x00 0x01 0x00 0x00 0x00 0x00 0x00 0x00 0xd4
			>;
			bl-off-cmd = <
				0x83 0x00 0x00 0x02 0x00 0x00 0x00 0x00 0x00 0x00 0x85
			>;
			panel-mode-setting {
				panel-mode-width = <1920>;
				panel-mode-height = <1080>;
				panel-mode-hfp = <40>;
				panel-mode-hsa = <42>;
				panel-mode-hbp = <78>;
				panel-mode-vfp = <24>;
				panel-mode-vsa = <3>;
				panel-mode-vbp = <9>;
				panel-mode-vrefresh = <60>;
				panel-mode-lppf = <1>;
				panel-mode-width-mm = <129>;
				panel-mode-height-mm = <64>;
			};
		};
	};
	superframe_setting: setting3 {
		ser-super-frame = <1>;

		ser-init-cmd = <
			0x0002 0x73 0x0
			0x0053 0x10 0x0
			0x0057 0x21 0x0
			0x0332 0x4e 0x0
			0x0333 0xe4 0x0
			0x0004 0xf2 0x0
			0x0308 0x5c 0x0
			0x0311 0x03 0x0
			0x0331 0x03 0x0
			0x0330 0x06 0x0
			0x031c 0x98 0x0
			0x0321 0x24 0x0
			0x031d 0x98 0x0
			0x0322 0x24 0x0
			0x0326 0xe4 0x0
			0x03a4 0xc1 0x0
			0x032a 0x07 0x0
			0x0002 0x73 0x5
		>;
		ser-deinit-cmd = <
			0x0010 0x80 0x20
		>;
		ser-timing-cmd = <
			0x385 0x50 0x0
			0x386 0x02 0x0
			0x387 0x00 0x0
			0x3a5 0x18 0x0
			0x3a7 0x00 0x0
			0x3a6 0xa0 0x0
			0x3a8 0x38 0x0
			0x3a9 0x04 0x0
			0x3aa 0x50 0x0
			0x3ac 0x0a 0x0
			0x3ab 0x00 0x0
			0x3ad 0x00 0x0
			0x3ae 0x0f 0x0
		>;
		serdes-dual-setting-cmd = <
			0 0x0010 0x21 100
			1 0x0000 0x90 0
			2 0x0073 0x31 0
			2 0x0042 0x36 0
			2 0x0043 0x34 0
			0 0x0010 0x22 100
			1 0x0000 0x94 0
			3 0x0073 0x32 0
			3 0x0042 0x38 0
			3 0x0043 0x34 0
			0 0x0010 0x23 100
			3 0x0050 0x01 0
		>;
		ser-lut-cmd = <
		>;
		des-link-status-cmd = <
			0x001f 0x18 0x0
		>;
		desdef {
			des-i2c-addr = <0x4c>;
			bl-i2c-addr = <0x1a>;
			bl-dummy-i2c-addr = <0x1f>;
		};
		desa {
			des-i2c-addr = <0x48>;
			bl-i2c-addr = <0x1b>;
			des-init-cmd = <
				0x01ce 0x4c 0x0
				0x06ff 0x11 0x0
			>;
			link-indicate-cmd = <
				0x06ff 0x11 0x0
			>;
			bl-on-cmd = <
				0x83 0x50 0x00 0x01 0x00 0x00 0x00 0x00 0x00 0x00 0xd4
			>;
			bl-off-cmd = <
				0x83 0x00 0x00 0x02 0x00 0x00 0x00 0x00 0x00 0x00 0x85
			>;
			panel-mode-setting {
				panel-mode-width = <1920>;
				panel-mode-height = <1080>;
				panel-mode-hfp = <40>;
				panel-mode-hsa = <41>;
				panel-mode-hbp = <79>;
				panel-mode-vfp = <24>;
				panel-mode-vsa = <3>;
				panel-mode-vbp = <9>;
				panel-mode-vrefresh = <60>;
				panel-mode-lppf = <1>;
				panel-mode-width-mm = <129>;
				panel-mode-height-mm = <64>;
			};
		};
		desb {
			des-i2c-addr = <0x4a>;
			bl-i2c-addr = <0x1c>;
			des-init-cmd = <
				0x01ce 0x4c 0x0
				0x06ff 0x22 0x0
			>;
			link-indicate-cmd = <
				0x06ff 0x22 0x0
			>;
			bl-on-cmd = <
				0x83 0x50 0x00 0x01 0x00 0x00 0x00 0x00 0x00 0x00 0xd4
			>;
			bl-off-cmd = <
				0x83 0x00 0x00 0x02 0x00 0x00 0x00 0x00 0x00 0x00 0x85
			>;
			panel-mode-setting {
				panel-mode-width = <1920>;
				panel-mode-height = <1080>;
				panel-mode-hfp = <40>;
				panel-mode-hsa = <41>;
				panel-mode-hbp = <79>;
				panel-mode-vfp = <24>;
				panel-mode-vsa = <3>;
				panel-mode-vbp = <9>;
				panel-mode-vrefresh = <60>;
				panel-mode-lppf = <1>;
				panel-mode-width-mm = <129>;
				panel-mode-height-mm = <64>;
			};
		};
	};
};

&mipi_tx_config0 {
	status = "disabled";
};

&mipi_tx_config1 {
	status = "disabled";
};

&mipi_tx_config2 {
	status = "disabled";
};

&panel_edp {
	status = "disabled";
	panel-name = "HuaYang";
	panel-mode = "signal-setting";
	use-default-setting = <1>;

	BoTai{
		signal-setting{
			width-mm = <129>;
			height-mm = <64>;
			panel-timing {
				clock-frequency = <139526400>;
				hactive = <1920>;
				vactive = <1080>;
				hsync-len = <40>;
				hfront-porch = <40>;
				hback-porch = <80>;
				vfront-porch = <24>;
				vback-porch = <10>;
				vsync-len = <2>;
			};
		};

		superframe-setting{
			width-mm = <129>;
			height-mm = <64>;
			panel-timing {
				clock-frequency = <278553600>;
				hactive = <3840>;
				vactive = <1080>;
				hsync-len = <80>;
				hfront-porch = <80>;
				hback-porch = <160>;
				vfront-porch = <24>;
				vback-porch = <10>;
				vsync-len = <2>;
			};
		};
	};

	HuaYang{
		signal-setting{
			width-mm = <129>;
			height-mm = <64>;
			panel-timing {
				clock-frequency = <139526400>;
				hactive = <1920>;
				vactive = <1080>;
				hsync-len = <40>;
				hfront-porch = <40>;
				hback-porch = <80>;
				vfront-porch = <24>;
				vback-porch = <10>;
				vsync-len = <2>;
			};
		};

		superframe-setting{
			width-mm = <129>;
			height-mm = <64>;
			panel-timing {
				clock-frequency = <278553600>;
				hactive = <3840>;
				vactive = <1080>;
				hsync-len = <80>;
				hfront-porch = <80>;
				hback-porch = <160>;
				vfront-porch = <24>;
				vback-porch = <10>;
				vsync-len = <2>;
			};
		};
	};

	YW-1080{
		signal-setting{
			width-mm = <129>;
			height-mm = <64>;
			panel-timing {
				clock-frequency = <158709600>;
				hactive = <1920>;
				vactive = <1080>;
				hsync-len = <20>;
				hfront-porch = <14>;
				hback-porch = <20>;
				vfront-porch = <230>;
				vback-porch = <28>;
				vsync-len = <2>;
			};
		};

		superframe-setting{
			width-mm = <129>;
			height-mm = <64>;
			panel-timing {
				clock-frequency = <317419200>;
				hactive = <3840>;
				vactive = <1080>;
				hsync-len = <40>;
				hfront-porch = <28>;
				hback-porch = <40>;
				vfront-porch = <230>;
				vback-porch = <28>;
				vsync-len = <2>;
			};
		};
	};

	YW-720{
		signal-setting{
			width-mm = <129>;
			height-mm = <64>;
			panel-timing {
				clock-frequency = <88135920>;
				hactive = <1920>;
				vactive = <720>;
				hsync-len = <16>;
				hfront-porch = <44>;
				hback-porch = <24>;
				vfront-porch = <7>;
				vback-porch = <4>;
				vsync-len = <2>;
			};
		};

		superframe-setting{
			width-mm = <129>;
			height-mm = <64>;
			panel-timing {
				clock-frequency = <265970880>;
				hactive = <3840>;
				vactive = <720>;
				hsync-len = <32>;
				hfront-porch = <88>;
				hback-porch = <48>;
				vfront-porch = <14>;
				vback-porch = <8>;
				vsync-len = <4>;
			};
		};
	};

	port {
		panel_edp_in: endpoint {
			remote-endpoint = <&serdes_edp_out>;
		};
	};
};

&panel_dp {
	status = "disabled";
	panel-name = "HuaYang";
	panel-mode = "signal-setting";
	use-default-setting = <1>;

	BoTai{
		signal-setting{
			width-mm = <129>;
			height-mm = <64>;
			panel-timing {
				clock-frequency = <139526400>;
				hactive = <1920>;
				vactive = <1080>;
				hsync-len = <40>;
				hfront-porch = <40>;
				hback-porch = <80>;
				vfront-porch = <24>;
				vback-porch = <10>;
				vsync-len = <2>;
			};
		};

		superframe-setting{
			width-mm = <129>;
			height-mm = <64>;
			panel-timing {
				clock-frequency = <278553600>;
				hactive = <3840>;
				vactive = <1080>;
				hsync-len = <80>;
				hfront-porch = <80>;
				hback-porch = <160>;
				vfront-porch = <24>;
				vback-porch = <10>;
				vsync-len = <2>;
			};
		};
	};

	HuaYang{
		signal-setting{
			width-mm = <129>;
			height-mm = <64>;
			panel-timing {
				clock-frequency = <139526400>;
				hactive = <1920>;
				vactive = <1080>;
				hsync-len = <40>;
				hfront-porch = <40>;
				hback-porch = <80>;
				vfront-porch = <24>;
				vback-porch = <10>;
				vsync-len = <2>;
			};
		};

		superframe-setting{
			width-mm = <129>;
			height-mm = <64>;
			panel-timing {
				clock-frequency = <278553600>;
				hactive = <3840>;
				vactive = <1080>;
				hsync-len = <80>;
				hfront-porch = <80>;
				hback-porch = <160>;
				vfront-porch = <24>;
				vback-porch = <10>;
				vsync-len = <2>;
			};
		};
	};

	YW-1080{
		signal-setting{
			width-mm = <129>;
			height-mm = <64>;
			panel-timing {
				clock-frequency = <158709600>;
				hactive = <1920>;
				vactive = <1080>;
				hsync-len = <20>;
				hfront-porch = <14>;
				hback-porch = <20>;
				vfront-porch = <230>;
				vback-porch = <28>;
				vsync-len = <2>;
			};
		};

		superframe-setting{
			width-mm = <129>;
			height-mm = <64>;
			panel-timing {
				clock-frequency = <317419200>;
				hactive = <3840>;
				vactive = <1080>;
				hsync-len = <40>;
				hfront-porch = <28>;
				hback-porch = <40>;
				vfront-porch = <230>;
				vback-porch = <28>;
				vsync-len = <2>;
			};
		};
	};

	YW-720{
		signal-setting{
			width-mm = <129>;
			height-mm = <64>;
			panel-timing {
				clock-frequency = <88135920>;
				hactive = <1920>;
				vactive = <720>;
				hsync-len = <16>;
				hfront-porch = <44>;
				hback-porch = <24>;
				vfront-porch = <7>;
				vback-porch = <4>;
				vsync-len = <2>;
			};
		};

		superframe-setting{
			width-mm = <129>;
			height-mm = <64>;
			panel-timing {
				clock-frequency = <265970880>;
				hactive = <3840>;
				vactive = <720>;
				hsync-len = <32>;
				hfront-porch = <88>;
				hback-porch = <48>;
				vfront-porch = <14>;
				vback-porch = <8>;
				vsync-len = <4>;
			};
		};
	};

	port {
		panel_dp_in: endpoint {
			remote-endpoint = <&serdes_dp_out>;
		};
	};
};

&panel_dp_mst_one {
	compatible = "panel-serdes-dp-mst1";
	status = "disabled";
	panel-name = "HuaYang";
	panel-mode = "signal-setting";
	use-default-setting = <1>;

	BoTai{
		signal-setting{
			width-mm = <129>;
			height-mm = <64>;
			panel-timing {
				clock-frequency = <139526400>;
				hactive = <1920>;
				vactive = <1080>;
				hsync-len = <40>;
				hfront-porch = <40>;
				hback-porch = <80>;
				vfront-porch = <24>;
				vback-porch = <10>;
				vsync-len = <2>;
			};
		};

		superframe-setting{
			width-mm = <129>;
			height-mm = <64>;
			panel-timing {
				clock-frequency = <278553600>;
				hactive = <3840>;
				vactive = <1080>;
				hsync-len = <80>;
				hfront-porch = <80>;
				hback-porch = <160>;
				vfront-porch = <24>;
				vback-porch = <10>;
				vsync-len = <2>;
			};
		};
	};

	HuaYang{
		signal-setting{
			width-mm = <129>;
			height-mm = <64>;
			panel-timing {
				clock-frequency = <139526400>;
				hactive = <1920>;
				vactive = <1080>;
				hsync-len = <40>;
				hfront-porch = <40>;
				hback-porch = <80>;
				vfront-porch = <24>;
				vback-porch = <10>;
				vsync-len = <2>;
			};
		};

		superframe-setting{
			width-mm = <129>;
			height-mm = <64>;
			panel-timing {
				clock-frequency = <278553600>;
				hactive = <3840>;
				vactive = <1080>;
				hsync-len = <80>;
				hfront-porch = <80>;
				hback-porch = <160>;
				vfront-porch = <24>;
				vback-porch = <10>;
				vsync-len = <2>;
			};
		};
	};

	YW-1080{
		signal-setting{
			width-mm = <129>;
			height-mm = <64>;
			panel-timing {
				clock-frequency = <158709600>;
				hactive = <1920>;
				vactive = <1080>;
				hsync-len = <20>;
				hfront-porch = <14>;
				hback-porch = <20>;
				vfront-porch = <230>;
				vback-porch = <28>;
				vsync-len = <2>;
			};
		};

		superframe-setting{
			width-mm = <129>;
			height-mm = <64>;
			panel-timing {
				clock-frequency = <317419200>;
				hactive = <3840>;
				vactive = <1080>;
				hsync-len = <40>;
				hfront-porch = <28>;
				hback-porch = <40>;
				vfront-porch = <230>;
				vback-porch = <28>;
				vsync-len = <2>;
			};
		};
	};

	YW-720{
		signal-setting{
			width-mm = <129>;
			height-mm = <64>;
			panel-timing {
				clock-frequency = <88135920>;
				hactive = <1920>;
				vactive = <720>;
				hsync-len = <16>;
				hfront-porch = <44>;
				hback-porch = <24>;
				vfront-porch = <7>;
				vback-porch = <4>;
				vsync-len = <2>;
			};
		};

		superframe-setting{
			width-mm = <129>;
			height-mm = <64>;
			panel-timing {
				clock-frequency = <265970880>;
				hactive = <3840>;
				vactive = <720>;
				hsync-len = <32>;
				hfront-porch = <88>;
				hback-porch = <48>;
				vfront-porch = <14>;
				vback-porch = <8>;
				vsync-len = <4>;
			};
		};
	};

	port {
		panel_dp_mst_in1: endpoint {
			remote-endpoint = <&serdes_dp_mst_out1>;
		};
	};
};
